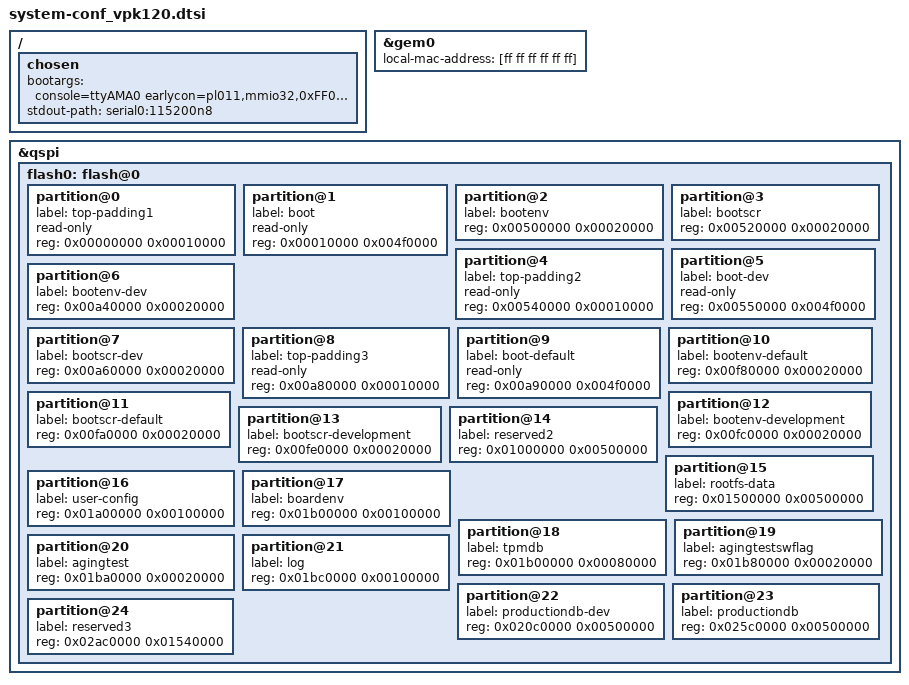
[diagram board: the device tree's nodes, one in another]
/*
 * CAUTION: This file is automatically generated by PetaLinux SDK.
 * DO NOT modify this file
 */


/ {
	chosen {
		bootargs = "console=ttyAMA0 earlycon=pl011,mmio32,0xFF000000,115200n8 clk_ignore_unused root=/dev/ram0 rw";
		stdout-path = "serial0:115200n8";
	};
};

&gem0 {
	local-mac-address = [ff ff ff ff ff ff];
};

&qspi {
	#address-cells = <1>;
	#size-cells = <0>;
	flash0: flash@0 {
		partition@0 {
			label = "top-padding1";
			read-only;
			reg = <0x00000000 0x00010000>;
		};
		partition@1 {
			label = "boot";
			read-only;
			reg = <0x00010000 0x004f0000>;
		};
		partition@2 {
			label = "bootenv";
			reg = <0x00500000 0x00020000>;
		};
		partition@3 {
			label = "bootscr";
			reg = <0x00520000 0x00020000>;
		};
		partition@4 {
			label = "top-padding2";
			read-only;
			reg = <0x00540000 0x00010000>;
		};
		partition@5 {
			label = "boot-dev";
			read-only;
			reg = <0x00550000 0x004f0000>;
		};
		partition@6 {
			label = "bootenv-dev";
			reg = <0x00a40000 0x00020000>;
		};
		partition@7 {
			label = "bootscr-dev";
			reg = <0x00a60000 0x00020000>;
		};
		partition@8 {
			label = "top-padding3";
			read-only;
			reg = <0x00a80000 0x00010000>;
		};
		partition@9 {
			label = "boot-default";
			read-only;
			reg = <0x00a90000 0x004f0000>;
		};
		partition@10 {
			label = "bootenv-default";
			reg = <0x00f80000 0x00020000>;
		};
		partition@11 {
			label = "bootscr-default";
			reg = <0x00fa0000 0x00020000>;
		};
		partition@12 {
			label = "bootenv-development";
			reg = <0x00fc0000 0x00020000>;
		};
		partition@13 {
			label = "bootscr-development";
			reg = <0x00fe0000 0x00020000>;
		};
		partition@14 {
			label = "reserved2";
			reg = <0x01000000 0x00500000>;
		};
		partition@15 {
			label = "rootfs-data";
			reg = <0x01500000 0x00500000>;
		};
		partition@16 {
			label = "user-config";
			reg = <0x01a00000 0x00100000>;
		};
		partition@17 {
			label = "boardenv";
			reg = <0x01b00000 0x00100000>;
		};
		partition@18 {
			label = "tpmdb";
			reg = <0x01b00000 0x00080000>;
		};
		partition@19 {
			label = "agingtestswflag";
			reg = <0x01b80000 0x00020000>;
		};
		partition@20 {
			label = "agingtest";
			reg = <0x01ba0000 0x00020000>;
		};
		partition@21 {
			label = "log";
			reg = <0x01bc0000 0x00100000>;
		};
		partition@22 {
			label = "productiondb-dev";
			reg = <0x020c0000 0x00500000>;
		};
		partition@23 {
			label = "productiondb";
			reg = <0x025c0000 0x00500000>;
		};
		partition@24 {
			label = "reserved3";
			reg = <0x02ac0000 0x01540000>;
		};
	};
};

